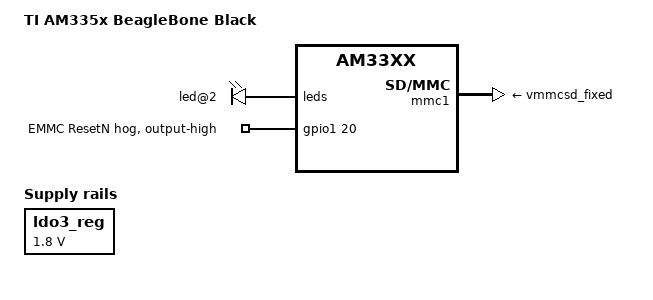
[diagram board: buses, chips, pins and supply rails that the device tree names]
/*
 * Copyright (C) 2012 Texas Instruments Incorporated - http://www.ti.com/
 *
 * This program is free software; you can redistribute it and/or modify
 * it under the terms of the GNU General Public License version 2 as
 * published by the Free Software Foundation.
 * 
 * Also I fucked with this version of it. 
 */

/dts-v1/;
#include "am33xx.dtsi"
#include "am335x-bone-common.dtsi"

/* #include "am33xx-overlay-edma-fix.dtsi" */

/* pruss: pick one: */

/*
 * /etc/modprobe.d/pruss-blacklist.conf
 *
 * blacklist uio_pruss
 */

#include "am33xx-pruss-rproc.dtsi"

/ {
	model = "TI AM335x BeagleBone Black";
	compatible = "ti,am335x-bone-black", "ti,am335x-bone", "ti,am33xx";
	// Turn off blinky heartbeat (I sleep in here dammit)
	leds {
		led@2 {
			linux,default-trigger = "none";
		};
	};
	// Pins conflict with PRU
	hdmi {
		status = "disabled";
	};
	sound {
		status = "disabled";
	};
};

&ldo3_reg {
	regulator-min-microvolt = <1800000>;
	regulator-max-microvolt = <1800000>;
	regulator-always-on;
};

&mmc1 {
	vmmc-supply = <&vmmcsd_fixed>;
};

&cpu0_opp_table {
	/*
	 * All PG 2.0 silicon may not support 1GHz but some of the early
	 * BeagleBone Blacks have PG 2.0 silicon which is guaranteed
	 * to support 1GHz OPP so enable it for PG 2.0 on this board.
	 */
	oppnitro@1000000000 {
		opp-supported-hw = <0x06 0x0100>;
	};
};

/* EMMC in reset */
&gpio1 {
	emmc_rst {
		gpio-hog;
		gpios = <20 0>;
		output-high;
		line-name = "EMMC ResetN";
	};
};

&lcdc { // I think this might be redundant with hdmi { ...disabled... } above
	status = "disabled";  		/* Disable HDMI due to pin mux conflicts with PRU Cape */
};

&mcasp0 { // No fucking clue what this does
	status = "disabled";
};
// Set all the PRU pins to output
&am33xx_pinmux {
	pru_zero_fucks_pins: pru_zero_fucks_pins {
		pinctrl-single,pins = <
			AM33XX_IOPAD(0x990, PIN_OUTPUT_PULLDOWN | MUX_MODE5) 	/* PRU0 R30_0	P9_31 */
			AM33XX_IOPAD(0x994, PIN_OUTPUT_PULLDOWN | MUX_MODE5) 	/* PRU0 R30_1	P9_29 */ 
			AM33XX_IOPAD(0x998, PIN_OUTPUT_PULLDOWN | MUX_MODE5)	/* PRU0 R30_2   P9_30 */
			AM33XX_IOPAD(0x99C, PIN_OUTPUT_PULLDOWN | MUX_MODE5)	/* PRU0 R30_3   P9_28 */
			AM33XX_IOPAD(0x964, PIN_INPUT_PULLDOWN | MUX_MODE7) 	/* Nothing 	P9_42 */
		 	AM33XX_IOPAD(0x9a0, PIN_OUTPUT_PULLDOWN | MUX_MODE5)	/* PRU0 R30_4   P9_42 Same pin as above */
			AM33XX_IOPAD(0x9A4, PIN_OUTPUT_PULLDOWN | MUX_MODE5)	/* PRU0 R30_5   P9_27 */
			AM33XX_IOPAD(0x9B4, PIN_INPUT_PULLDOWN | MUX_MODE7) 	/* Nothing 	P9_41 */
		 	AM33XX_IOPAD(0x9a8, PIN_OUTPUT_PULLDOWN | MUX_MODE5)	/* PRU0 R30_6   P9_41 Same pin as above */
			AM33XX_IOPAD(0x9AC, PIN_OUTPUT_PULLDOWN | MUX_MODE5)	/* PRU0 R30_7   P9_25 */
			AM33XX_IOPAD(0x830, PIN_OUTPUT_PULLDOWN | MUX_MODE6)	/* PRU0 R30_14  P8_12 */
			AM33XX_IOPAD(0x834, PIN_OUTPUT_PULLDOWN | MUX_MODE6)	/* PRU0 R30_15  P8_11 */

			AM33XX_IOPAD(0x8A0, PIN_OUTPUT_PULLDOWN | MUX_MODE5)	/* PRU1 R30_0	P8_45 */
			AM33XX_IOPAD(0x8A4, PIN_OUTPUT_PULLDOWN | MUX_MODE5)    /* PRU1 R30_1	P8_46 */
			AM33XX_IOPAD(0x8A8, PIN_OUTPUT_PULLDOWN | MUX_MODE5)    /* PRU1 R30_2	P8_43 */
			AM33XX_IOPAD(0x8Ac, PIN_OUTPUT_PULLDOWN | MUX_MODE5)    /* PRU1 R30_3	P8_44 */
			AM33XX_IOPAD(0x8B0, PIN_OUTPUT_PULLDOWN | MUX_MODE5)    /* PRU1 R30_4	P8_41 */
			AM33XX_IOPAD(0x8B4, PIN_OUTPUT_PULLDOWN | MUX_MODE5)    /* PRU1 R30_5	P8_42 */
			AM33XX_IOPAD(0x8B8, PIN_OUTPUT_PULLDOWN | MUX_MODE5)    /* PRU1 R30_6	P8_39 */
			AM33XX_IOPAD(0x8BC, PIN_OUTPUT_PULLDOWN | MUX_MODE5)    /* PRU1 R30_7	P8_40 */
			AM33XX_IOPAD(0x8E0, PIN_OUTPUT_PULLDOWN | MUX_MODE5)    /* PRU1 R30_8	P8_27 */
			AM33XX_IOPAD(0x8E8, PIN_OUTPUT_PULLDOWN | MUX_MODE5)    /* PRU1 R30_9	P8_29 */
			AM33XX_IOPAD(0x8E4, PIN_OUTPUT_PULLDOWN | MUX_MODE5)    /* PRU1 R30_10	P8_28 */
			AM33XX_IOPAD(0x8EC, PIN_OUTPUT_PULLDOWN | MUX_MODE5)    /* PRU1 R30_11	P8_30 */

			AM33XX_IOPAD(0x880, PIN_OUTPUT_PULLDOWN | MUX_MODE5)    /* PRU1 R30_12	P8_21 */
			AM33XX_IOPAD(0x884, PIN_OUTPUT_PULLDOWN | MUX_MODE5)    /* PRU1 R30_13	P8_20 */
		>;
	};
};
&pruss {
	pinctrl-names = "default";
	pinctrl-0 = <&pru_zero_fucks_pins>;
};
